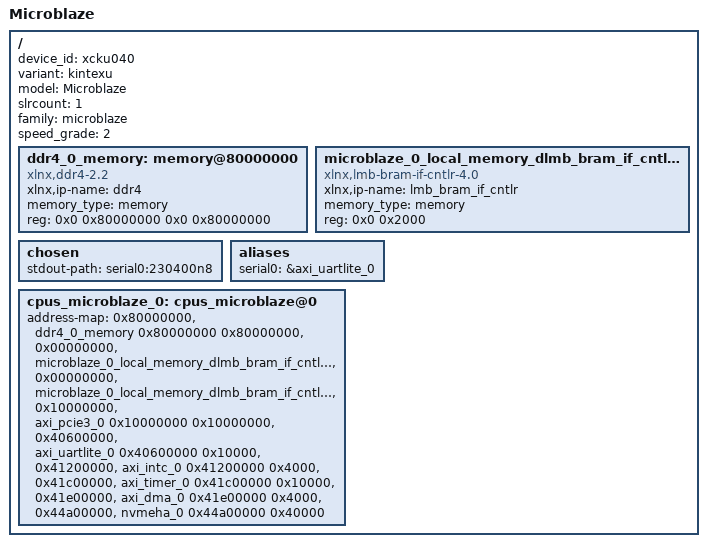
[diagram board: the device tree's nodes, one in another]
/dts-v1/;
#include "pl.dtsi"
/ {
	device_id = "xcku040";
	#address-cells = <1>;
	variant = "kintexu";
	model = "Microblaze";
	#size-cells = <1>;
	slrcount = <1>;
	family = "microblaze";
	speed_grade = "2";
	ddr4_0_memory: memory@80000000 {
		compatible = "xlnx,ddr4-2.2";
		xlnx,ip-name = "ddr4";
		device_type = "memory";
		memory_type = "memory";
		reg = <0x0 0x80000000 0x0 0x80000000>;
	};
	microblaze_0_local_memory_dlmb_bram_if_cntlr_memory: memory@0 {
		compatible = "xlnx,lmb-bram-if-cntlr-4.0" , "mmio-sram";
		xlnx,ip-name = "lmb_bram_if_cntlr";
		device_type = "memory";
		memory_type = "memory";
		reg = <0x0 0x2000>;
	};
	chosen {
		stdout-path = "serial0:230400n8";
	};
	aliases {
		serial0 = &axi_uartlite_0;
	};
	cpus_microblaze_0: cpus_microblaze@0 {
		address-map = <0x80000000 &ddr4_0_memory 0x80000000 0x80000000>, 
			      <0x00000000 &microblaze_0_local_memory_dlmb_bram_if_cntlr_memory 0x00000000 0x2000>, 
			      <0x00000000 &microblaze_0_local_memory_dlmb_bram_if_cntlr 0x00000000 0x2000>, 
			      <0x10000000 &axi_pcie3_0 0x10000000 0x10000000>, 
			      <0x40600000 &axi_uartlite_0 0x40600000 0x10000>, 
			      <0x41200000 &axi_intc_0 0x41200000 0x4000>, 
			      <0x41c00000 &axi_timer_0 0x41c00000 0x10000>, 
			      <0x41e00000 &axi_dma_0 0x41e00000 0x4000>, 
			      <0x44a00000 &nvmeha_0 0x44a00000 0x40000>;
		#ranges-address-cells = <0x1>;
		#ranges-size-cells = <0x1>;
	};
};
